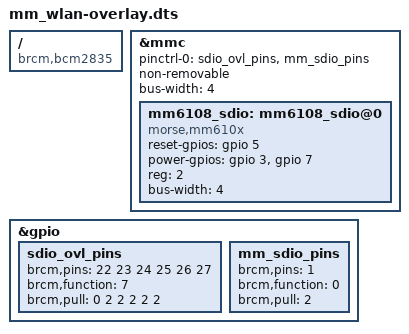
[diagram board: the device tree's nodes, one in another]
/dts-v1/;
/plugin/;

/ {
	compatible = "brcm,bcm2835", "brcm,bcm2836", "brcm,bcm2708", "brcm,bcm2709", "brcm,bcm2711";

	fragment@0 {
		target = <&mmc>;
		wifi_ovl: __overlay__ {
			pinctrl-0 = <&sdio_ovl_pins &mm_sdio_pins>;
			pinctrl-names = "default";
			non-removable;
			bus-width = <4>;
			status = "okay";
			#address-cells = <1>;
			#size-cells = <0>;
			mm6108_sdio: mm6108_sdio@0 {
				compatible = "morse,mm610x";
				reset-gpios = <&gpio 5 0>;
				power-gpios = <&gpio 3 0>,
				              <&gpio 7 0>;
				status = "okay";
				reg = <2>;
				bus-width = <4>;
			};
		};
	};

	fragment@1 {
		target = <&gpio>;
		__overlay__ {
			sdio_ovl_pins: sdio_ovl_pins {
				brcm,pins = <22 23 24 25 26 27>;
				brcm,function = <7>; /* ALT3 = SD1 */
				brcm,pull = <0 2 2 2 2 2>;
			};
			mm_sdio_pins: mm_sdio_pins {
				brcm,pins = <1>; /* CHIP-IRQ */
				brcm,function = <0>;
				brcm,pull = <2>;
			};
		};
	};
};
